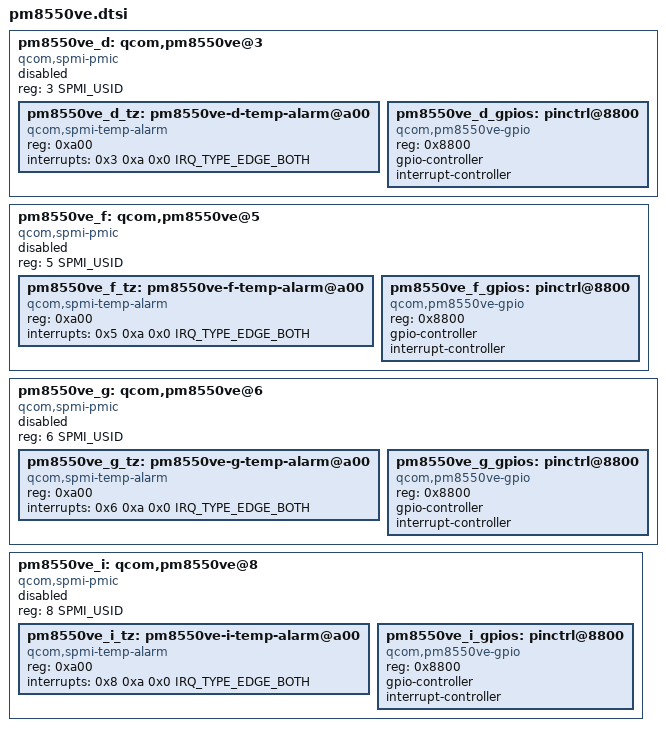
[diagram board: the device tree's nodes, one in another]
// SPDX-License-Identifier: BSD-3-Clause
/*
 * Copyright (c) 2022-2024 Qualcomm Innovation Center, Inc. All rights reserved.
 */

#include <dt-bindings/interrupt-controller/irq.h>
#include <dt-bindings/spmi/spmi.h>


pm8550ve_d: qcom,pm8550ve@3 {
	compatible = "qcom,spmi-pmic";
	reg = <3 SPMI_USID>;
	#address-cells = <1>;
	#size-cells = <0>;
	status = "disabled";

	pm8550ve_d_tz: pm8550ve-d-temp-alarm@a00 {
		compatible = "qcom,spmi-temp-alarm";
		reg = <0xa00>;
		interrupts = <0x3 0xa 0x0 IRQ_TYPE_EDGE_BOTH>;
		#thermal-sensor-cells = <0>;
	};

	pm8550ve_d_gpios: pinctrl@8800 {
		compatible = "qcom,pm8550ve-gpio";
		reg = <0x8800>;
		gpio-controller;
		#gpio-cells = <2>;
		interrupt-controller;
		#interrupt-cells = <2>;
	};
};

pm8550ve_f: qcom,pm8550ve@5 {
	compatible = "qcom,spmi-pmic";
	reg = <5 SPMI_USID>;
	#address-cells = <1>;
	#size-cells = <0>;
	status = "disabled";

	pm8550ve_f_tz: pm8550ve-f-temp-alarm@a00 {
		compatible = "qcom,spmi-temp-alarm";
		reg = <0xa00>;
		interrupts = <0x5 0xa 0x0 IRQ_TYPE_EDGE_BOTH>;
		#thermal-sensor-cells = <0>;
	};

	pm8550ve_f_gpios: pinctrl@8800 {
		compatible = "qcom,pm8550ve-gpio";
		reg = <0x8800>;
		gpio-controller;
		#gpio-cells = <2>;
		interrupt-controller;
		#interrupt-cells = <2>;
	};
};

pm8550ve_g: qcom,pm8550ve@6 {
	compatible = "qcom,spmi-pmic";
	reg = <6 SPMI_USID>;
	#address-cells = <1>;
	#size-cells = <0>;
	status = "disabled";

	pm8550ve_g_tz: pm8550ve-g-temp-alarm@a00 {
		compatible = "qcom,spmi-temp-alarm";
		reg = <0xa00>;
		interrupts = <0x6 0xa 0x0 IRQ_TYPE_EDGE_BOTH>;
		#thermal-sensor-cells = <0>;
	};

	pm8550ve_g_gpios: pinctrl@8800 {
		compatible = "qcom,pm8550ve-gpio";
		reg = <0x8800>;
		gpio-controller;
		#gpio-cells = <2>;
		interrupt-controller;
		#interrupt-cells = <2>;
	};
};

pm8550ve_i: qcom,pm8550ve@8 {
	compatible = "qcom,spmi-pmic";
	reg = <8 SPMI_USID>;
	#address-cells = <1>;
	#size-cells = <0>;
	status = "disabled";

	pm8550ve_i_tz: pm8550ve-i-temp-alarm@a00 {
		compatible = "qcom,spmi-temp-alarm";
		reg = <0xa00>;
		interrupts = <0x8 0xa 0x0 IRQ_TYPE_EDGE_BOTH>;
		#thermal-sensor-cells = <0>;
	};

	pm8550ve_i_gpios: pinctrl@8800 {
		compatible = "qcom,pm8550ve-gpio";
		reg = <0x8800>;
		gpio-controller;
		#gpio-cells = <2>;
		interrupt-controller;
		#interrupt-cells = <2>;
	};
};
